# J7AEP_GPU_BXS464_WRAP0_GPU_SS_0_CORE_MMRS register map
Vendor: Texas Instruments
Registers are 64-bit, access per field, reset 0x0 unless marked. A register's access mark holds for its fields unless they carry their own. Offsets are as the file gives them; [hi:lo] are bit positions; lines under a group give offsets from that group; {n}, {i} and the like mark numbered series; 'fields as' and 'values as' point back to an identical list.

## J7AEP_GPU_BXS464_WRAP0_GPU_SS_0_CORE_MMRS (part 4 of 5)
0x2010 CORE_MMRS_RGX_CR_PM_MMU_STACK_POLICY — This register enables the PM to drain pages for MMU from the dedicated mmu free list stack. (no-pagable) It is static register which can not be changed in the run-time.
  [0] OP rw — when this bit is '1', PM will try to drain pages from the dedicated mmu free list stack
0x2018 CORE_MMRS_RGX_CR_PM_TA_MMU_FSTACK_BASE — Effective on loading of the MMU TA free list loading , this register defines the base address of the mmu free list stack being referenced during TA processing.
  [39:4] ADDR rw — 1TB Addressable, 128 bits aligned Base Address for MMU TA free list stack
0x2020 CORE_MMRS_RGX_CR_PM_TA_MMU_FSTACK_STATUS ro — Note: this is the pointer pointing to the MMU TA free stack top. (4KB page pointer)
  [21:0] TOP — This status register indicated the mmu ta context free list pointer status.
0x2028 CORE_MMRS_RGX_CR_PM_TA_MMU_FSTACK — Defines the start of the stack pointer regarding to the MMU free list stack
  [21:0] STARTOF_TOP rw — This register defines the head pointer of the mmu free list in terms of 4K free pages in the free list stack, effective on a loading of the MMU TA free list
0x2030 CORE_MMRS_RGX_CR_PM_START_OF_MMU_TACONTEXT
  [21:0] ALLOCATED_MMUPAGE rw — Start of MMU Freelists TA pages[4KB] on loading of the MMU TA context
0x2038 CORE_MMRS_RGX_CR_PM_TASK_TA_MMU_FSTACK_FREE_LOAD
  [0] PENDING wo — A write into this register will cause the TA MMU free list context to be loaded from the relevant configuration registers
0x2040 CORE_MMRS_RGX_CR_PM_3D_MMU_FSTACK_BASE — Effective on loading of the MMU 3D free list loading , this register defines the base address of the mmu free list stack being referenced during 3D processing.
  fields as CORE_MMRS_RGX_CR_PM_TA_MMU_FSTACK_BASE
0x2048 CORE_MMRS_RGX_CR_PM_3D_MMU_FSTACK_STATUS ro — Note: this is the pointer pointing to the MMU TA free stack top. (4KB page pointer)
  fields as CORE_MMRS_RGX_CR_PM_TA_MMU_FSTACK_STATUS
0x2050 CORE_MMRS_RGX_CR_PM_3D_MMU_FSTACK — Defines the start of the stack pointer regarding to the MMU free list stack Effective on a 3D MMU fstack load
  fields as CORE_MMRS_RGX_CR_PM_TA_MMU_FSTACK
0x2058 CORE_MMRS_RGX_CR_PM_START_OF_MMU_3DCONTEXT — Effective on a 3D MMU fstack load
  [21:0] ALLOCATED_MMUPAGE rw — Start of MMU Freelists 3D pages[4KB] on loading of the MMU TA context
0x2060 CORE_MMRS_RGX_CR_PM_TASK_3D_MMU_FSTACK_FREE_LOAD
  [0] PENDING wo — A write into this register will cause the 3D MMU free list context to be loaded from the relevant configuration registers
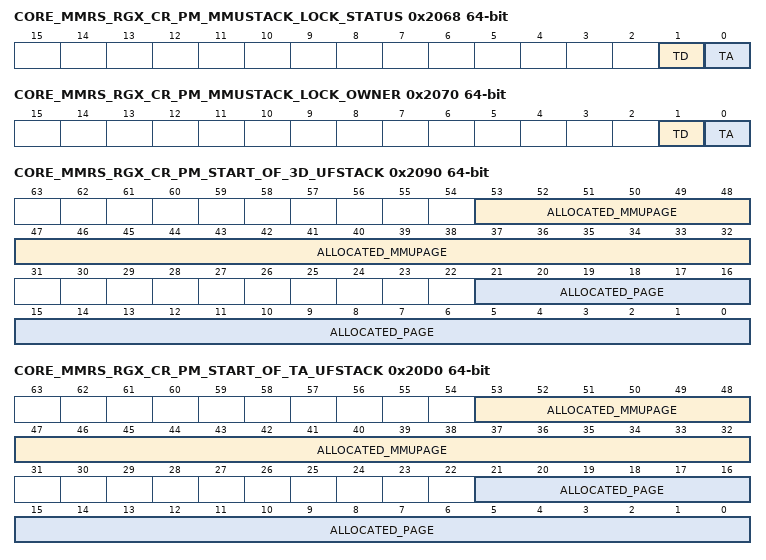
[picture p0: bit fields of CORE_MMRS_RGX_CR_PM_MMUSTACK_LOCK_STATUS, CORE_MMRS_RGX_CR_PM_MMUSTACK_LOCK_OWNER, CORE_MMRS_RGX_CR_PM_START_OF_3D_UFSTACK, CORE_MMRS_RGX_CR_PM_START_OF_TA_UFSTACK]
0x2068 CORE_MMRS_RGX_CR_PM_MMUSTACK_LOCK_STATUS ro
  [1] TD — Bit 1: 3D MMU free list Lock Status. 0 idle/ 1 used
  [0] TA — Bit 0: TA MMU free list Lock Status. 0 idle/ 1 used.
0x2070 CORE_MMRS_RGX_CR_PM_MMUSTACK_LOCK_OWNER ro
  [1] TD — Bit 1 :3D free list Lock owner. 0 PMA / 1 PMD
  [0] TA — Bit 0: TA free list Lock Owner. 0 PMA / 1 PMD.
0x2078 CORE_MMRS_RGX_CR_PM_3D_UFSTACK_BASE — Effective on load of the Unified Free List Stack, this register defines the base address of the unified free list stack being referenced.
  [39:4] ADDR rw — 1TB Addressable, 128 bits aligned Base Address for unified free list stack base address
0x2080 CORE_MMRS_RGX_CR_PM_3D_UFSTACK — Note: each 16GB 4KB addressable page (22 bits) is rounded to dword aligned Effective on load of the Unified Free List Stack,
  [21:0] STARTOF_TOP rw — This register defines the unified free list stack pointer @ loading time. It is 4K page.
0x2088 CORE_MMRS_RGX_CR_PM_3D_UFSTACK_STATUS ro — Note: this is the pointer pointing to the ufstack top. (4KB page pointer)
  [21:0] TOP — This status register indicated the unified free list stack pointer status.
0x2090 CORE_MMRS_RGX_CR_PM_START_OF_3D_UFSTACK — Effective on load of the Unified Free List Stack,
  [53:32] ALLOCATED_MMUPAGE rw — Start of MMU Pages allocated from the Unifed Free List Stack On Loading
  [21:0] ALLOCATED_PAGE rw — Start of TA pages[4KB] on loading of the Unified Free List Stack
0x2098 CORE_MMRS_RGX_CR_PM_3D_UFSTACK_PAGE_STATUS ro
  [21:0] OP — The number of Unified Free list pages currently allocated for the TA
0x20A0 CORE_MMRS_RGX_CR_PM_3D_UFSTACK_MMUPAGE_STATUS ro
  [21:0] OP — The number of Unified Free list pages currently allocated for the MMU
0x20A8 CORE_MMRS_RGX_CR_PM_TASK_3D_UFSTACK_LOAD ro
  [0] PENDING — pending status register corresponding to the ustack loading operation, it will become '1' when this pm_task_ufstack_load being written and deassert until the operation is done
0x20B0 CORE_MMRS_RGX_CR_PM_TASK_TA_UFSTACK_LOAD ro
  fields as CORE_MMRS_RGX_CR_PM_TASK_3D_UFSTACK_LOAD
0x20B8 CORE_MMRS_RGX_CR_PM_TA_UFSTACK_BASE — Effective on load of the Unified Free List Stack, this register defines the base address of the unified free list stack being referenced.
  fields as CORE_MMRS_RGX_CR_PM_3D_UFSTACK_BASE
0x20C0 CORE_MMRS_RGX_CR_PM_TA_UFSTACK — Note: each 16GB 4KB addressable page (22 bits) is rounded to dword aligned Effective on the loading of the Unified Free List Stack,
  fields as CORE_MMRS_RGX_CR_PM_3D_UFSTACK
0x20C8 CORE_MMRS_RGX_CR_PM_TA_UFSTACK_STATUS ro — Note: this is the pointer pointing to the ufstack top. (4KB page pointer)
  fields as CORE_MMRS_RGX_CR_PM_3D_UFSTACK_STATUS
0x20D0 CORE_MMRS_RGX_CR_PM_START_OF_TA_UFSTACK
  fields as CORE_MMRS_RGX_CR_PM_START_OF_3D_UFSTACK
0x20D8 CORE_MMRS_RGX_CR_PM_TA_UFSTACK_PAGE_STATUS ro
  fields as CORE_MMRS_RGX_CR_PM_3D_UFSTACK_PAGE_STATUS
0x20E0 CORE_MMRS_RGX_CR_PM_TA_UFSTACK_MMUPAGE_STATUS ro
  fields as CORE_MMRS_RGX_CR_PM_3D_UFSTACK_MMUPAGE_STATUS
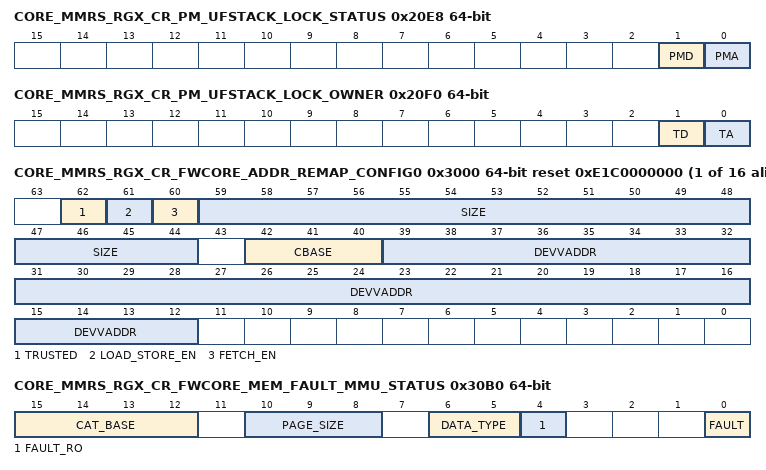
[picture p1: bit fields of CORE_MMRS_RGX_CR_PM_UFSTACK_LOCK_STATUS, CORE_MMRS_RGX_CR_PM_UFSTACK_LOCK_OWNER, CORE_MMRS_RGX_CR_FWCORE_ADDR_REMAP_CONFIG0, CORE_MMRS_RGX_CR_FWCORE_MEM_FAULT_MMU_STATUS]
0x20E8 CORE_MMRS_RGX_CR_PM_UFSTACK_LOCK_STATUS ro — In rogue architecture, there is a unified free list whereby shared across multiple context. This lock status indicating the stack owner at the time being. Note PMA and PMD can not acquire the lock @ the same time
  [1] PMD — Bit 1: Page DeAllocation Manger is grabing the lock. 0:idle/ 1 used.
  [0] PMA — Bit 0: Page Allocation Manger is grabing the lock. 0:idle/ 1 used.
0x20F0 CORE_MMRS_RGX_CR_PM_UFSTACK_LOCK_OWNER ro
  fields as CORE_MMRS_RGX_CR_PM_MMUSTACK_LOCK_OWNER
0x20F8 CORE_MMRS_RGX_CR_PM_UFSTACK_POLICY — This register enables the PM to drain pages from the unified free list stack It is a static configuration register
  [0] OP rw — when this bit is '1', PM will try to drain pages from the unified free list stack as long as the ta free list do not have enough pages for the allocation
0x2100 CORE_MMRS_RGX_CR_PM_VFP_TRAN_EN — This register enables the PM to another level of transfrom which is from Virtial Page to VirtualPhysical Page number
  [0] OP rw — when this bit is '1', PM will try to another level of lookup between virtual page and the virtual physical page
0x2108 CORE_MMRS_RGX_CR_PM_TA_VFP_TABLE_BASE — Effective on loading TA context, this register defines the base address of the virtual-physical page table during TA processing.
  [39:4] ADDR rw — 1TB Addressable, 128 bits aligned Base Address for TA context page tables in the DPM module
0x2110 CORE_MMRS_RGX_CR_PM_3D_VFP_TABLE_BASE — Effective on loading 3D context, this register defines the base address of the virtual-physical page table during 3D processing.
  [39:4] ADDR rw — 1TB Addressable, 128 bits aligned Base Address for 3D context page tables in the DPM module
{0x3000+8i} CORE_MMRS_RGX_CR_FWCORE_ADDR_REMAP_CONFIG{i} reset 0xE1C0000000 (i=0..15) — Override swerv memory access for this region
  [62] TRUSTED rw — Set whether accesses in the this region are trusted
  [61] LOAD_STORE_EN rw — Region enabled for loads/stores
  [60] FETCH_EN rw — Region enabled for instruction fetches
  [59:44] SIZE rw — Region mapped window size
  [42:40] CBASE rw — MMU catalogue base index. Indices 0-7 are supported
  [39:12] DEVVADDR rw — Base output address [4k aligned]
0x3090 CORE_MMRS_RGX_CR_FWCORE_BOOT — Boot the RISCV CPU
  [0] ENABLE rw
0x3098 CORE_MMRS_RGX_CR_FWCORE_RESET_ADDR reset 0xC0000000 — Swerv reset address
  [31:1] ADDR rw — Reset address for the core
0x30A0 CORE_MMRS_RGX_CR_FWCORE_WRAPPER_NMI_ADDR reset 0xC0001000 — Non-Maskable Interrupt address
  [31:1] ADDR rw
0x30A8 CORE_MMRS_RGX_CR_FWCORE_WRAPPER_NMI_EVENT — Issue a Non-Maskable Interrupt to RISCV
  [0] TRIGGER_EN rw
0x30B0 CORE_MMRS_RGX_CR_FWCORE_MEM_FAULT_MMU_STATUS — Indicates a fault has occurred on the CPU MMU and provides details of the fault. Writing any value will clear the fault and allow subsequent faults to be reported.
  [15:12] CAT_BASE rw — Catalogue base address number
  [10:8] PAGE_SIZE rw
  [6:5] DATA_TYPE rw — MMU data type that was invalid [on valid fault]
  [4] FAULT_RO rw — Indicates read-only fault['1'] or valid fault['0']
  [0] FAULT rw — Indicates a fault has occured
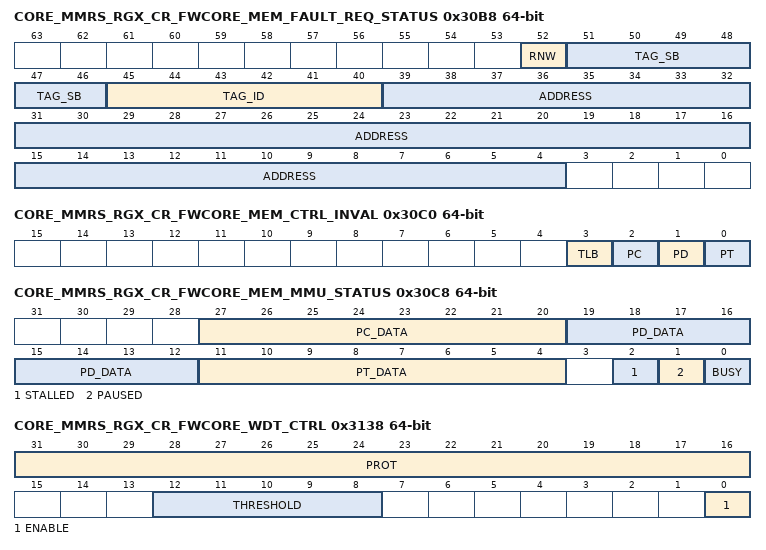
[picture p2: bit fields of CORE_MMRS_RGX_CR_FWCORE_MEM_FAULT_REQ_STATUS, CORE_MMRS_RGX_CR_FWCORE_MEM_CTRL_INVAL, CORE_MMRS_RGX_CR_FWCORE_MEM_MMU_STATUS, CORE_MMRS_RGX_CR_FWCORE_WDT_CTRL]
0x30B8 CORE_MMRS_RGX_CR_FWCORE_MEM_FAULT_REQ_STATUS ro — Provides details of the request that faulted on the CPU MMU
  [52] RNW, [51:46] TAG_SB, [45:40] TAG_ID, [39:4] ADDRESS
0x30C0 CORE_MMRS_RGX_CR_FWCORE_MEM_CTRL_INVAL — Invalidation bits allowing CPU BIF/MMU to clear when invalidation complete
  [3] TLB rw, [2] PC rw, [1] PD rw, [0] PT rw
0x30C8 CORE_MMRS_RGX_CR_FWCORE_MEM_MMU_STATUS ro — General CPU MMU status
  [27:20] PC_DATA, [19:12] PD_DATA, [11:4] PT_DATA, [2] STALLED, [1] PAUSED, [0] BUSY
0x30D8 CORE_MMRS_RGX_CR_FWCORE_MEM_READS_EXT_STATUS ro — Outstanding read data external to CPU MMU
  [11:0] MMU
0x30E0 CORE_MMRS_RGX_CR_FWCORE_MEM_READS_INT_STATUS ro — Outstanding 256-bit read data in return data FIFO for CPU MMU
  [10:0] MMU
0x30E8 CORE_MMRS_RGX_CR_FWCORE_WRAPPER_FENCE — Writing to this register offset will cause the CPU wrapper to emit a write fence to memory. Reading from this register has no effect. This register does not actually exist anywhere in RTL - it is a reserved address.
  [0] ID rw
{0x30F0+8i} CORE_MMRS_RGX_CR_FWCORE_MEM_CAT_BASE{i} (i=0..7)
  [39:12] ADDR rw
0x3130 CORE_MMRS_RGX_CR_FWCORE_WDT_RESET — A '1' may be written to this register to reset the watchdog timer count. The count will be reset to 0x0 whether or not the timer is currently enabled.
  [0] EN wo
0x3138 CORE_MMRS_RGX_CR_FWCORE_WDT_CTRL — Watchdog timer control register.
  [31:16] PROT wo — Writes to this register must set these bits to 0xABCD for the writes to THRESHOLD and ENABLE to take effect. These bits are read as 0x0000
  [12:8] THRESHOLD wo — Logarithmic threshold. When the counter bit indexed by the value in this field transitions from 0 to 1 the WDT module output pulse is asserted and the count is reset to 0.
  [0] ENABLE wo — '1' - WDT enabled. '0' - WDT disabled.
0x3140 CORE_MMRS_RGX_CR_FWCORE_WDT_COUNT ro — Read only register returns the current value of the watchdog timer count.
  [31:0] VALUE
0x3148 CORE_MMRS_RGX_CR_RISCV_MTIME_SET rw — Writing to this register updates the Timer counter. On the following ticks the counter will be incremented based on the newly written value.
  [63:0] VALUE
0x3150 CORE_MMRS_RGX_CR_RISCV_MTIME_CMP rw — Writing to this register updates the Timer compare value and at the same time clears the sticky bit of the timer interrupt output.
  [63:0] VALUE
0x3158 CORE_MMRS_RGX_CR_RISCV_MTIME_STAT ro — Shows the momentary value of the 64 bit Timer counter.
  [63:0] VALUE
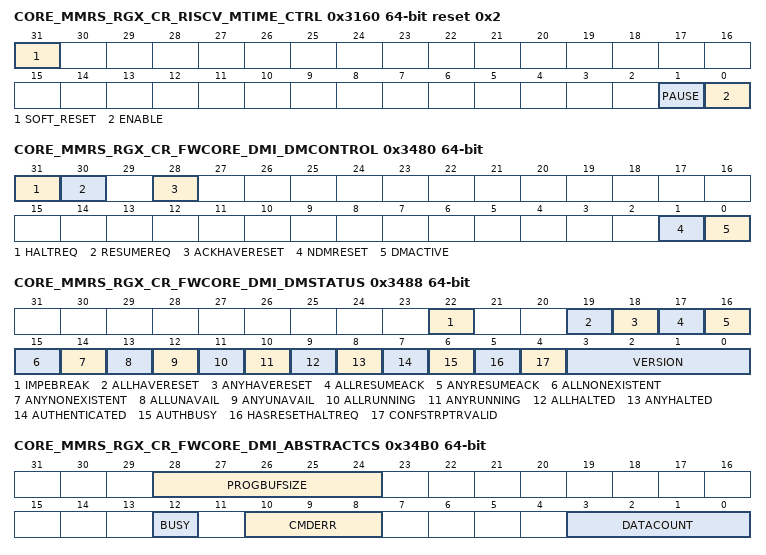
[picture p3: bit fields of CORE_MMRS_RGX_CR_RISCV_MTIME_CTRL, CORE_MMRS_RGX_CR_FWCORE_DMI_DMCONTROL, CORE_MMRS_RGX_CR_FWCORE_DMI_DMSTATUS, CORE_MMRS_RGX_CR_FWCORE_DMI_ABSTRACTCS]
0x3160 CORE_MMRS_RGX_CR_RISCV_MTIME_CTRL reset 0x2 — Control register.
  [31] SOFT_RESET rw — When high, the counter, the MTIME_SET & MTIME_CMP registers and the sticky interrupt are all forced to zero
  [1] PAUSE rw — When high, the timer is not being incremented by tick pulses, but can still be written using the MTIME_SET registers.
  [0] ENABLE rw — When high, the timer interrupt output is enabled. The counter itself is not affected by this bit.
0x3168 CORE_MMRS_RGX_CR_FWCORE_IDLE reset 0x1 — Top-level idle control register
  [0] ENABLE rw — Set to 0x0 overwrites the value of GPU_IDLE to 0x0, set to 0x1 makes GPU Idle dependent on top level idles
{0x3400+8i} CORE_MMRS_RGX_CR_FWCORE_DMI_RESERVED{i:02} ro (i=0..3) — This address is mapped to the FW CPU debug port. Do not use
0x3420 CORE_MMRS_RGX_CR_FWCORE_DMI_DATA0 — RISC-V Debug Module Interface - Basic read/write register that may be read or changed by abstract commands.
  [31:0] VAL rw
0x3428 CORE_MMRS_RGX_CR_FWCORE_DMI_DATA1 — RISC-V Debug Module Interface - Basic read/write register that may be read or changed by abstract commands.
  [31:0] VAL rw
{0x33E0+8i} CORE_MMRS_RGX_CR_FWCORE_DMI_RESERVED{i} ro (i=10..19) — This address is mapped to the FW CPU debug port. Do not use
0x3480 CORE_MMRS_RGX_CR_FWCORE_DMI_DMCONTROL — RISC-V Debug Module Interface - This register controls the overall Debug Module as well as the currently selected harts.
  [31] HALTREQ rw, [30] RESUMEREQ rw, [28] ACKHAVERESET rw, [1] NDMRESET rw, [0] DMACTIVE rw
0x3488 CORE_MMRS_RGX_CR_FWCORE_DMI_DMSTATUS ro — RISC-V Debug Module Interface - This register reports status for the overall Debug Module as well as the currently selected harts.
  [22] IMPEBREAK, [19] ALLHAVERESET, [18] ANYHAVERESET, [17] ALLRESUMEACK, [16] ANYRESUMEACK, [15] ALLNONEXISTENT, [14] ANYNONEXISTENT, [13] ALLUNAVAIL, [12] ANYUNAVAIL, [11] ALLRUNNING, [10] ANYRUNNING, [9] ALLHALTED, [8] ANYHALTED, [7] AUTHENTICATED, [6] AUTHBUSY, [5] HASRESETHALTREQ, [4] CONFSTRPTRVALID, [3:0] VERSION
{0x33F0+8i} CORE_MMRS_RGX_CR_FWCORE_DMI_RESERVED{i} ro (i=20..23) — This address is mapped to the FW CPU debug port. Do not use
0x34B0 CORE_MMRS_RGX_CR_FWCORE_DMI_ABSTRACTCS — RISC-V Debug Module Interface - Abstract Control and Status
  [28:24] PROGBUFSIZE rw, [12] BUSY rw, [10:8] CMDERR rw, [3:0] DATACOUNT rw
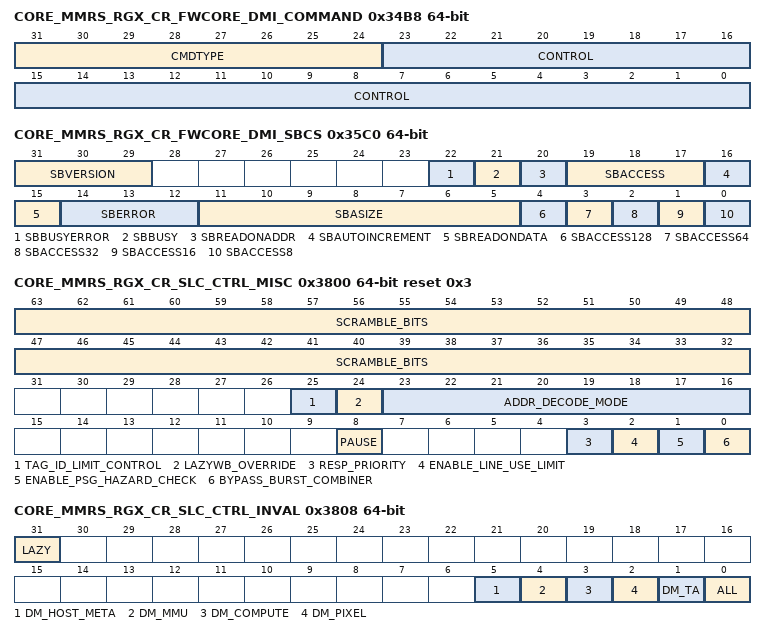
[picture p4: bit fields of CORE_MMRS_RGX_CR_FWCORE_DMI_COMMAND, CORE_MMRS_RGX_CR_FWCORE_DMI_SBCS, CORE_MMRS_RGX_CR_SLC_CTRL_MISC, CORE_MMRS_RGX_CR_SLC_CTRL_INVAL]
0x34B8 CORE_MMRS_RGX_CR_FWCORE_DMI_COMMAND — RISC-V Debug Module Interface - Abstract Command
  [31:24] CMDTYPE rw, [23:0] CONTROL rw
{0x33D0+8i} CORE_MMRS_RGX_CR_FWCORE_DMI_RESERVED{i} ro (i=30..39) — This address is mapped to the FW CPU debug port. Do not use
{0x2B60+8i} CORE_MMRS_RGX_CR_FWCORE_DMI_RESERVED{i} ro (i=310..331) — This address is mapped to the FW CPU debug port. Do not use
0x35C0 CORE_MMRS_RGX_CR_FWCORE_DMI_SBCS — RISC-V Debug Module Interface - System Bus Access Control and Status
  [31:29] SBVERSION rw, [22] SBBUSYERROR rw, [21] SBBUSY rw, [20] SBREADONADDR rw, [19:17] SBACCESS rw, [16] SBAUTOINCREMENT rw, [15] SBREADONDATA rw, [14:12] SBERROR rw, [11:5] SBASIZE rw, [4] SBACCESS128 rw, [3] SBACCESS64 rw, [2] SBACCESS32 rw, [1] SBACCESS16 rw, [0] SBACCESS8 rw
0x35C8 CORE_MMRS_RGX_CR_FWCORE_DMI_SBADDRESS0 — RISC-V Debug Module Interface - System Bus Address
  [31:0] ADDRESS rw
0x35D0 CORE_MMRS_RGX_CR_FWCORE_DMI_RESERVED40 ro — This address is mapped to the FW CPU debug port. Do not use
0x35D8 CORE_MMRS_RGX_CR_FWCORE_DMI_RESERVED41 ro — This address is mapped to the FW CPU debug port. Do not use
{0x35E0+8i} CORE_MMRS_RGX_CR_FWCORE_DMI_SBDATA{i} (i=0..3) — RISC-V Debug Module Interface - System Bus Data Words
  [31:0] DATA rw
0x3600 CORE_MMRS_RGX_CR_FWCORE_DMI_HALTSUM0 ro — RISC-V Debug Module Interface - Halt Summary 0
  [31:0] VAL
0x3800 CORE_MMRS_RGX_CR_SLC_CTRL_MISC reset 0x3 — SLC control registers
  [63:32] SCRAMBLE_BITS rw — Pattern of bits used to determine the Cache Bank in Address Decode mode 0x21. The actual Cache Bank to use is determined by indexing into the 32 Scramble Bits using the 5 LSB's of the Hash result and then XORing this with Bit 6 of the incoming address to give a single bit result
  [25] TAG_ID_LIMIT_CONTROL rw — Controls the number of external memory tag IDs available to SLC
  [24] LAZYWB_OVERRIDE rw — Override cache policy of requests with lazy write back to write back
  [23:16] ADDR_DECODE_MODE rw — Address decoding used to determine cache bank from the address: 0x00 = Bit 6 = 64 byte 0x01 = Bit 7 = 128 byte 0x10 = Simple XOR based address hash 1, see SLC TRM 0x11 = Simple XOR based address hash 2, see SLC TRM 0x20 = PVR address hash using an XOR reduce of the hash, see SLC TRM 0x21 = PVR address hash using Scramble Bits above, see SLC TRM
  [8] PAUSE rw — Pause the SLC
  [3] RESP_PRIORITY rw — Priority setting between Hit and Miss on return response. Default is round robin and set to 1 if miss needs priority over hit
  [2] ENABLE_LINE_USE_LIMIT rw — Enable the use of cache line limits
  [1] ENABLE_PSG_HAZARD_CHECK rw — Enable the hazard checking of PSG writes, only turn off if strict write ordering is guaranteed in the memory fabric
  [0] BYPASS_BURST_COMBINER rw — Disable the burst combiner on the external memory interface
0x3808 CORE_MMRS_RGX_CR_SLC_CTRL_INVAL — SLC Invalidate control. Note that per Data Master operations only invalidate entries that have been referenced solely by the specified Data Master, any cache lines referenced by multiple Data Masters will not be affected by a per Data Master invalidate operation and will remain valid.
  [31] LAZY wo — Advanced mode of operation whereby other requestors are not blocked whilst the Invalidate is in progress
  [5] DM_HOST_META wo — When set, invalidate all SLC entries referenced solely by the HOST or META
  [4] DM_MMU wo — When set, invalidate all SLC entries referenced solely by the MMU
  [3] DM_COMPUTE wo — When set, invalidate all SLC entries referenced solely by the COMPUTE data master
  [2] DM_PIXEL wo — When set, invalidate all SLC entries referenced solely by the PIXEL data master
  [1] DM_TA wo — When set, invalidate all SLC entries referenced solely by the TA group which includes VERTEX, TESSELLATOR & STREAM_OUT data masters
  [0] ALL wo — When set, invalidate all SLC entries
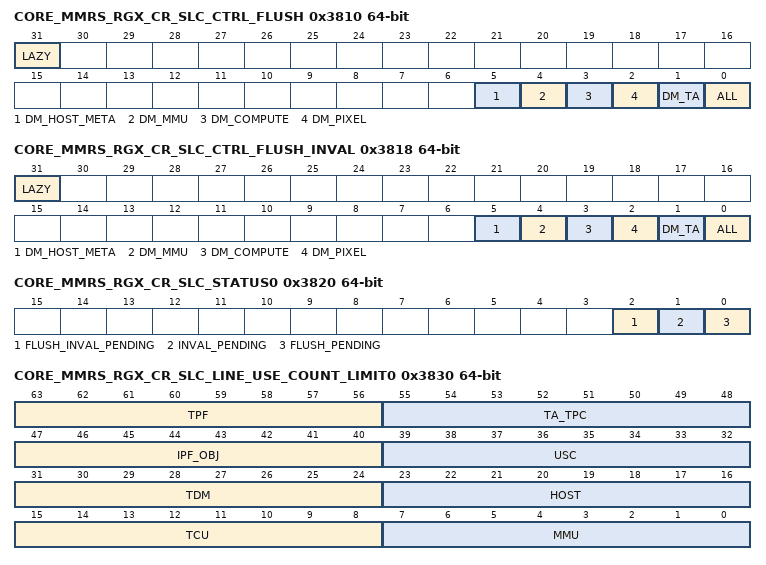
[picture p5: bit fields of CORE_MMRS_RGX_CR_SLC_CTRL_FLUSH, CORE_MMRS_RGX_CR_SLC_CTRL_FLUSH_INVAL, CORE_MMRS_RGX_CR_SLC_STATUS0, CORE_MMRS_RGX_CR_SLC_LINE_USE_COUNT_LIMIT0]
0x3810 CORE_MMRS_RGX_CR_SLC_CTRL_FLUSH — SLC Flush control. Note that per Data Master operations will flush any cache lines that have been made dirty by any writes from the specified Data Master.
  [31] LAZY wo — Advanced mode of operation whereby other requestors are not blocked whilst the Flush is in progress
  [5] DM_HOST_META wo — When set, flush all SLC entries made dirty by the HOST or META
  [4] DM_MMU wo — When set, flush all SLC entries made dirty by the MMU
  [3] DM_COMPUTE wo — When set, flush all SLC entries made dirty by the COMPUTE data master
  [2] DM_PIXEL wo — When set, flush all SLC entries made dirty by the PIXEL data master
  [1] DM_TA wo — When set, flush all SLC entries made dirty by the TA group which includes VERTEX, TESSELLATOR & STREAM_OUT data masters
  [0] ALL wo — When set, flush all SLC entries
0x3818 CORE_MMRS_RGX_CR_SLC_CTRL_FLUSH_INVAL — SLC Flush & Invalidate control. Note that per Data Master operations will flush any cache lines that have been made dirty by any writes from the specified Data Master. Combined Invalidate operation then only invalidates entries that have been referenced solely by the specified Data Master, any cache lines referenced by multiple Data Masters will not be affected by a per Data Master invalidate operation and will remain valid.
  [31] LAZY wo — Advanced mode of operation whereby other requestors are not blocked whilst the Flush Invalidate is in progress
  [5] DM_HOST_META wo — When set, flush all SLC entries made dirty by the HOST or META, then invalidate all SLC entries referenced solely by the HOST or META
  [4] DM_MMU wo — When set, flush all SLC entries made dirty by the MMU, then invalidate all SLC entries referenced solely by the MMU
  [3] DM_COMPUTE wo — When set, flush all SLC entries made dirty by the COMPUTE data master, then invalidate all SLC entries referenced solely by the COMPUTE data master
  [2] DM_PIXEL wo — When set, flush all SLC entries made dirty by the PIXEL data master, then invalidate all SLC entries referenced solely by the PIXEL data master
  [1] DM_TA wo — When set, flush all SLC entries made dirty by the TA group which includes VERTEX, TESSELLATOR & STREAM_OUT data masters, then invalidate all SLC entries referenced solely by the TA group which includes VERTEX, TESSELLATOR & STREAM_OUT data masters
  [0] ALL wo — When set, flush all SLC entries, then invalidate all SLC entries
0x3820 CORE_MMRS_RGX_CR_SLC_STATUS0 ro — Current status of Flush / Invalidate operations within the SLC
  [2] FLUSH_INVAL_PENDING — 1 indicates there is a pending request to perform a combined Flush Invalidate on the SLC
  [1] INVAL_PENDING — 1 indicates there is a pending request to Invalidate the SLC
  [0] FLUSH_PENDING — 1 indicates there is a pending request to Flush the SLC
0x3828 CORE_MMRS_RGX_CR_SLC_CTRL_BYPASS reset 0x3D1F00000000 — SLC Bypass control
  [59] REQ_TFBC_COMP_ZLS rw — Bypass SLC for TFBC_COMP ZLS requestor
  [58] REQ_TFBC_DECOMP_ZLS_HEADER rw — Bypass SLC for TFBC_DECOMP ZLS Header requestor
  [57] REQ_TFBC_DECOMP_TCU_HEADER rw — Bypass SLC for TFBC_DECOMP TCU Header requestor
  [56] REQ_TFBC_DECOMP_ZLS_DATA rw — Bypass SLC for TFBC_DECOMP ZLS Delta requestor
  [55] REQ_TFBC_DECOMP_TCU_DATA rw — Bypass SLC for TFBC_DECOMP TCU Delta requestor
  [54] REQ_TFBC_COMP_PBE rw — Bypass SLC for TFBC_COMP PBE requestor
  [53] REQ_TCU_DM_COMPUTE rw — Bypass SLC when DM is COMPUTE for TCU requests
  [52] PDSRW_NOLINEFILL rw — PDSRW nolinefill set
  [51] PBE_NOLINEFILL rw — PBE nolinefill set
  [49] REQ_IPF_RREQ rw — Bypass SLC for IPF [RREQ] requestor
  [48] REQ_IPF_CREQ rw — Bypass SLC for IPF [CREQ] requestor
  [47] REQ_IPF_PREQ rw — Bypass SLC for IPF [PREQ] requestor
  [46] REQ_IPF_DBSC rw — Bypass SLC for IPF [DBSC] requestor
  [45] REQ_TCU rw — Bypass SLC for TCU requests
  [44] REQ_PBE rw — Bypass SLC for PBE requestor
  [43] REQ_ISP rw — Bypass SLC for the ISP requestor
  [42] REQ_PM rw — Bypass SLC for the PM requestor
  [40] REQ_CDM rw — Bypass SLC for the CDM requestor
  [39] REQ_TSPF_PDS_STATE rw — Bypass SLC for the TSPF PDS STATE requestor
  [38] REQ_TSPF_DB rw — Bypass SLC for the TSPF DB requestor
  [37] REQ_TSPF_VTX_VAR rw — Bypass SLC for the TSPF VTX VAR requestor
  [36] REQ_VDM rw — Bypass SLC for VDM requestor
  [35] REQ_TA_PSG_STREAM rw — Bypass SLC for the TA [PSG Stream] requestor
  [34] REQ_TA_PSG_REGION rw — Bypass SLC for the TA [PSG Region] requestor
  [33] REQ_TA_VCE rw — Bypass SLC for the TA [VCE] requestor
  [32] REQ_TA_PPP rw — Bypass SLC for the TA [PPP] requestor
  [30] DM_PM_ALIST rw — Bypass SLC for the PM_ALIST data master
  [29] DM_PB_TE rw — Bypass SLC for the PB_TE data master
  [28] DM_PB_VCE rw — Bypass SLC for the PB_VCE data master
  [25] REQ_IPF_CPF rw — Bypass SLC for IPF [CPF] requestor
  [24] REQ_TPU rw — Bypass SLC for TPU requests coming from the MCU requestor
  [21] BYP_CC_N rw — Bypass SLC when Cache Coherency bit is not set
  [20] BYP_CC rw — Bypass SLC when Cache Coherency bit is set
  [19] REQ_MCU rw — Bypass SLC for the MCU requestor
  [18] REQ_PDS rw — Bypass SLC for the PDS requestor
  [17] REQ_TPF rw — Bypass SLC for the TPF requestor
  [16] REQ_TA_TPC rw — Bypass SLC for the TA [Tail Pointer Cache data] requestor
  [14] REQ_USC rw — Bypass SLC for the USC requestor
  [13] REQ_META rw — Bypass SLC for the META requestor
  [12] REQ_HOST rw — Bypass SLC for the Host requestor
  [11] REQ_MMU_PT rw — Bypass SLC for the MMU requestor [Page Table data]
  [10] REQ_MMU_PD rw — Bypass SLC for the MMU requestor [Page Directory data]
  [9] REQ_MMU_PC rw — Bypass SLC for the MMU requestor [Page Catalogue data]
  [5] DM_HOST_META rw — Bypass SLC the HOST/META data master
  [4] DM_MMU rw — Bypass SLC the MMU data master
  [3] DM_COMPUTE rw — Bypass SLC the COMPUTE data master
  [2] DM_PIXEL rw — Bypass SLC for the PIXEL data master
  [1] DM_TA rw — Bypass SLC for the TA group which includes VERTEX, TESSELLATOR & STREAM_OUT data masters
  [0] ALL rw — Bypass SLC for all requesters
0x3830 CORE_MMRS_RGX_CR_SLC_LINE_USE_COUNT_LIMIT0 rw — Define the maximum number of cache lines allowed to be allocated to each requester within the SLC. Note that values are specified per bank as a multiple of 4 cache lines with values of 0x0 denoting no limit. Also note that the specified values operate as soft limits rather than hard limits and at any given time a requestor may temporarily exceed its given cacheline limit by a small amount.
  [63:56] TPF — Maximum number of cachelines allocated to the TPF requestor
  [55:48] TA_TPC — Maximum number of cachelines allocated to the TA [Tail Pointer Cache data] requestor
  [47:40] IPF_OBJ — Maximum number of cachelines allocated to the IPF [Object data] requestor
  [39:32] USC — Maximum number of cachelines allocated to the USC requestor
  [31:24] TDM — Maximum number of cachelines allocated to the TDM requestor
  [23:16] HOST — Maximum number of cachelines allocated to the HOST requestor
  [15:8] TCU — Maximum number of cachelines allocated to the TCU requestor
  [7:0] MMU — Maximum number of cachelines allocated to the MMU requestor
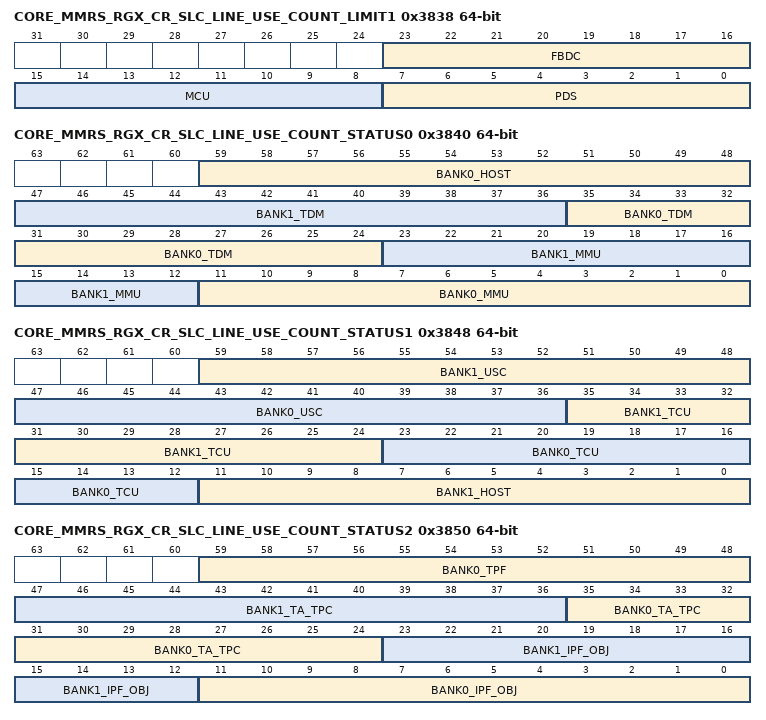
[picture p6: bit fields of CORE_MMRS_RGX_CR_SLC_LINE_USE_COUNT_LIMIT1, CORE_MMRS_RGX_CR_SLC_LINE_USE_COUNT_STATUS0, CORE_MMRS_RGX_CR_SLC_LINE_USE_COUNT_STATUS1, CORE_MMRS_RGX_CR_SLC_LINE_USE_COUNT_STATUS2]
0x3838 CORE_MMRS_RGX_CR_SLC_LINE_USE_COUNT_LIMIT1 — Define the maximum number of cache lines allowed to be allocated to each requester within the SLC. Note that values are specified per bank as a multiple of 4 cache lines with values of 0x0 denoting no limit. Also note that the specified values operate as soft limits rather than hard limits and at any given time a requestor may temporarily exceed its given cacheline limit by a small amount.
  [23:16] FBDC rw — Maximum number of cachelines allocated to the FBDC requestor
  [15:8] MCU rw — Maximum number of cachelines allocated to the MCU requestor
  [7:0] PDS rw — Maximum number of cachelines allocated to the PDS requestor
0x3840 CORE_MMRS_RGX_CR_SLC_LINE_USE_COUNT_STATUS0 ro — Number of cache lines currently allocated to each requester within the SLC. Values will constantly change when the core is active but will give a representative snapshot of cache usage.
  [59:48] BANK0_HOST — Number of cache lines in bank 0 currently allocated to the HOST
  [47:36] BANK1_TDM — Number of cache lines in bank 1 currently allocated to the TDM
  [35:24] BANK0_TDM — Number of cache lines in bank 0 currently allocated to the TDM
  [23:12] BANK1_MMU — Number of cache lines in bank 1 currently allocated to the MMU
  [11:0] BANK0_MMU — Number of cache lines in bank 0 currently allocated to the MMU
0x3848 CORE_MMRS_RGX_CR_SLC_LINE_USE_COUNT_STATUS1 ro — Number of cache lines currently allocated to each requester within the SLC. Values will constantly change when the core is active but will give a representative snapshot of cache usage.
  [59:48] BANK1_USC — Number of cache lines in bank 1 currently allocated to the USC
  [47:36] BANK0_USC — Number of cache lines in bank 0 currently allocated to the USC
  [35:24] BANK1_TCU — Number of cache lines in bank 1 currently allocated to the TCU
  [23:12] BANK0_TCU — Number of cache lines in bank 0 currently allocated to the TCU
  [11:0] BANK1_HOST — Number of cache lines in bank 1 currently allocated to the HOST
0x3850 CORE_MMRS_RGX_CR_SLC_LINE_USE_COUNT_STATUS2 ro — Number of cache lines currently allocated to each requester within the SLC. Values will constantly change when the core is active but will give a representative snapshot of cache usage.
  [59:48] BANK0_TPF — Number of cache lines in bank 0 currently allocated to the TPF
  [47:36] BANK1_TA_TPC — Number of cache lines in bank 1 currently allocated to the TA [Tail Pointer Cache data]
  [35:24] BANK0_TA_TPC — Number of cache lines in bank 0 currently allocated to the TA [Tail Pointer Cache data]
  [23:12] BANK1_IPF_OBJ — Number of cache lines in bank 1 currently allocated to the IPF [Object data]
  [11:0] BANK0_IPF_OBJ — Number of cache lines in bank 0 currently allocated to the IPF [Object data]
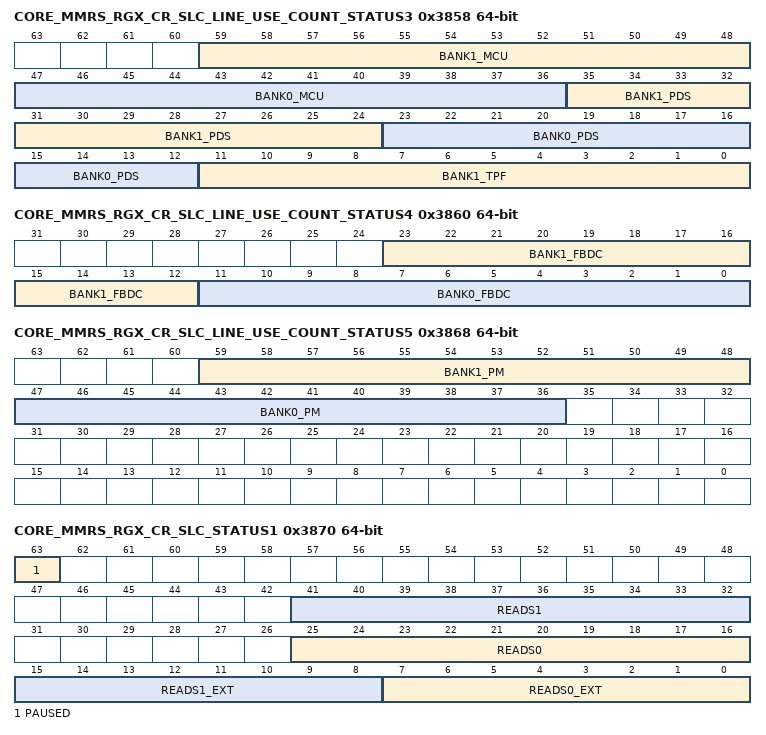
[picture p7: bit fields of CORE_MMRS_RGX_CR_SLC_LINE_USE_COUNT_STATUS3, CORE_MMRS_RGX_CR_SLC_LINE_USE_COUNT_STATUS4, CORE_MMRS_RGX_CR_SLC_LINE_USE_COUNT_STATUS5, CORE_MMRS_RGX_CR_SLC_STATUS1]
0x3858 CORE_MMRS_RGX_CR_SLC_LINE_USE_COUNT_STATUS3 ro — Number of cache lines currently allocated to each requester within the SLC. Values will constantly change when the core is active but will give a representative snapshot of cache usage.
  [59:48] BANK1_MCU — Number of cache lines in bank 1 currently allocated to the MCU
  [47:36] BANK0_MCU — Number of cache lines in bank 0 currently allocated to the MCU
  [35:24] BANK1_PDS — Number of cache lines in bank 1 currently allocated to the PDS
  [23:12] BANK0_PDS — Number of cache lines in bank 0 currently allocated to the PDS
  [11:0] BANK1_TPF — Number of cache lines in bank 1 currently allocated to the TPF
0x3860 CORE_MMRS_RGX_CR_SLC_LINE_USE_COUNT_STATUS4 ro — Number of cache lines currently allocated to each requester within the SLC. Values will constantly change when the core is active but will give a representative snapshot of cache usage.
  [23:12] BANK1_FBDC — Number of cache lines in bank 1 currently allocated to the FBDC
  [11:0] BANK0_FBDC — Number of cache lines in bank 0 currently allocated to the FBDC
0x3868 CORE_MMRS_RGX_CR_SLC_LINE_USE_COUNT_STATUS5 ro — Number of cache lines currently allocated to each requester within the SLC. Values will constantly change when the core is active but will give a representative snapshot of cache usage.
  [59:48] BANK1_PM — Number of cache lines in bank 1 currently allocated to the PM core
  [47:36] BANK0_PM — Number of cache lines in bank 0 currently allocated to the PM core
0x3870 CORE_MMRS_RGX_CR_SLC_STATUS1 ro — Current status of the SLC
  [63] PAUSED — All cache banks are Paused
  [41:32] READS1 — Number of items of read data SLC bank 1 has in internal pipeline FIFO's
  [25:16] READS0 — Number of items of read data SLC bank 0 has in internal pipeline FIFO's
  [15:8] READS1_EXT — Number of items of read data SLC bank 1 has outstanding from external memory
  [7:0] READS0_EXT — Number of items of read data SLC bank 0 has outstanding from external memory
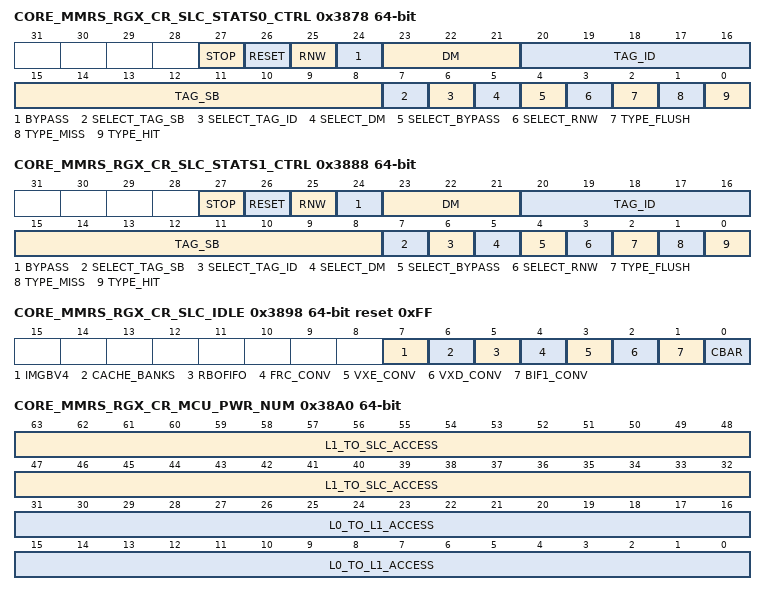
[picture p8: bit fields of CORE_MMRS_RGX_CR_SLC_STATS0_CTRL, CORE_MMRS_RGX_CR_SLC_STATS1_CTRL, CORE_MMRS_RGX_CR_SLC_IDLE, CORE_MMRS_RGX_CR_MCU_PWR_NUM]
0x3878 CORE_MMRS_RGX_CR_SLC_STATS0_CTRL — Configuration of the SLC Stats counters inside SLC bank 0. The type fields should be set to define the events that should be counted, then constraints should be added to specify particular requestors or types of request that should be counted.
  [27] STOP rw — Pause counting whilst this bit is set
  [26] RESET rw — Reset counter
  [25] RNW rw — If constraint set, 0x0 count only writes 0x1 count only reads
  [24] BYPASS rw — If constraint set, 0x0 count cached requests 0x1 count bypassed requests
  [23:21] DM rw — If constraint set, count only requests for the specified Data Master
  [20:16] TAG_ID rw — If constraint set, count only requests with the specified Tag ID
  [15:8] TAG_SB rw — If constraint set, count only requests with the specified sideband Tag
  [7] SELECT_TAG_SB rw — Include Tag sideband in constraints
  [6] SELECT_TAG_ID rw — Include Tag ID in constraints
  [5] SELECT_DM rw — Include Data Master in constraints
  [4] SELECT_BYPASS rw — Include Bypass enable in constraints
  [3] SELECT_RNW rw — Include Wead/Write select in constraints
  [2] TYPE_FLUSH rw — Count number of cache lines flushed
  [1] TYPE_MISS rw — Count number of misses
  [0] TYPE_HIT rw — Count number of hits
0x3880 CORE_MMRS_RGX_CR_SLC_STATS0_OUTPUT ro — Output of the SLC Stats counter inside SLC bank 0.
  [31:0] VALUE — Value of counter 0
0x3888 CORE_MMRS_RGX_CR_SLC_STATS1_CTRL — Configuration of the SLC Stats counters inside SLC bank 1. The type fields should be set to define the events that should be counted, then constraints should be added to specify particular requestors or types of request that should be counted.
  fields as CORE_MMRS_RGX_CR_SLC_STATS0_CTRL
0x3890 CORE_MMRS_RGX_CR_SLC_STATS1_OUTPUT ro — Output of the SLC Stats counter inside SLC bank 1.
  [31:0] VALUE — Value of counter 1
0x3898 CORE_MMRS_RGX_CR_SLC_IDLE ro reset 0xFF
  [7] IMGBV4 — IMG Bus v4 Module IDLE
  [6] CACHE_BANKS — Cache Bank IDLEs
  [5] RBOFIFO — Read Burst Order FIFO Module IDLE
  [4] FRC_CONV — FRC Module IDLE
  [3] VXE_CONV — Video Encode Converter Module IDLE
  [2] VXD_CONV — Video Decode Converter Module IDLE
  [1] BIF1_CONV — BIF128->256 Converter Module IDLE
  [0] CBAR — CrossBar Module IDLE
0x38A0 CORE_MMRS_RGX_CR_MCU_PWR_NUM ro — Power Monitoring register
  [63:32] L1_TO_SLC_ACCESS — Number of L1 to SLC accesses
  [31:0] L0_TO_L1_ACCESS — Number of L0 to L1 accesses. Both L0s in a DUST added together
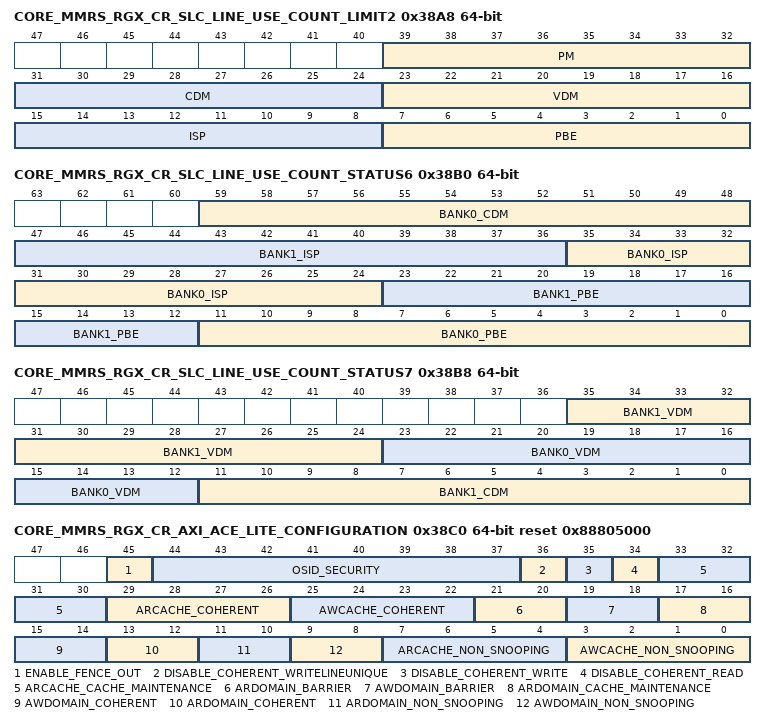
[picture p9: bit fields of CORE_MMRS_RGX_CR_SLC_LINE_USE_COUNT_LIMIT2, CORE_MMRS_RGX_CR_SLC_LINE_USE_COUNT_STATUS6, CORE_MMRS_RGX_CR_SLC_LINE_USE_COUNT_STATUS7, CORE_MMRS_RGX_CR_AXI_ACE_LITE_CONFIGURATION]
0x38A8 CORE_MMRS_RGX_CR_SLC_LINE_USE_COUNT_LIMIT2 — Define the maximum number of cache lines allowed to be allocated to each requester within the SLC. Note that values are specified per bank as a multiple of 4 cache lines with values of 0x0 denoting no limit. Also note that the specified values operate as soft limits rather than hard limits and at any given time a requestor may temporarily exceed its given cacheline limit by a small amount.
  [39:32] PM rw — Maximum number of cachelines allocated to the PM requestor
  [31:24] CDM rw — Maximum number of cachelines allocated to the CDM requestor
  [23:16] VDM rw — Maximum number of cachelines allocated to the VDM requestor
  [15:8] ISP rw — Maximum number of cachelines allocated to the ISP requestor
  [7:0] PBE rw — Maximum number of cachelines allocated to the PBE requestor
0x38B0 CORE_MMRS_RGX_CR_SLC_LINE_USE_COUNT_STATUS6 ro — Number of cache lines currently allocated to each requester within the SLC. Values will constantly change when the core is active but will give a representative snapshot of cache usage.
  [59:48] BANK0_CDM — Number of cache lines in bank 1 currently allocated to the CDM core
  [47:36] BANK1_ISP — Number of cache lines in bank 1 currently allocated to the ISP core
  [35:24] BANK0_ISP — Number of cache lines in bank 0 currently allocated to the ISP core
  [23:12] BANK1_PBE — Number of cache lines in bank 1 currently allocated to the PBE core
  [11:0] BANK0_PBE — Number of cache lines in bank 0 currently allocated to the PBE core
0x38B8 CORE_MMRS_RGX_CR_SLC_LINE_USE_COUNT_STATUS7 ro — Number of cache lines currently allocated to each requester within the SLC. Values will constantly change when the core is active but will give a representative snapshot of cache usage.
  [35:24] BANK1_VDM — Number of cache lines in bank 1 currently allocated to the VDM core
  [23:12] BANK0_VDM — Number of cache lines in bank 0 currently allocated to the VDM core
  [11:0] BANK1_CDM — Number of cache lines in bank 1 currently allocated to the CDM core
0x38C0 CORE_MMRS_RGX_CR_AXI_ACE_LITE_CONFIGURATION reset 0x88805000 — AXI ACE-LITE configuration registers
  [45] ENABLE_FENCE_OUT rw — SET to 1 to enable fence output to AXI
  [44:37] OSID_SECURITY rw — SET to 1 to disable secure reads/writes for each OSID
  [36] DISABLE_COHERENT_WRITELINEUNIQUE rw — SET to 1 to disable coherent write line uniques
  [35] DISABLE_COHERENT_WRITE rw — SET to 1 to disable coherent writes
  [34] DISABLE_COHERENT_READ rw — SET to 1 to disable coherent reads
  [33:30] ARCACHE_CACHE_MAINTENANCE rw — Read cache policy for cache maintenance transactions - bit[1] should be set to 1
  [29:26] ARCACHE_COHERENT rw — Read cache policy for coherent transactions - bit[1] should be set to 1
  [25:22] AWCACHE_COHERENT rw — Write cache policy for coherent transactions - bit[1] should be set to 1
  [21:20] ARDOMAIN_BARRIER rw — Read shareability domain for barrier transactions 00 = Non-Shareable 01 = Inner Shareable 10 = Outer Shareable 11 = System
  [19:18] AWDOMAIN_BARRIER rw — Write shareability domain for barrier transactions 00 = Non-Shareable 01 = Inner Shareable 10 = Outer Shareable 11 = System
  [17:16] ARDOMAIN_CACHE_MAINTENANCE rw — Read shareability domain for cache maintenance transactions 00 = Non-Shareable 01 = Inner Shareable 10 = Outer Shareable
  [15:14] AWDOMAIN_COHERENT rw — Write shareability domain for coherant transactions 01 = Inner Shareable 10 = Outer Shareable
  [13:12] ARDOMAIN_COHERENT rw — Read shareability domain for coherant transactions 01 = Inner Shareable 10 = Outer Shareable
  [11:10] ARDOMAIN_NON_SNOOPING rw — Read shareability domain for non-snooping transactions 00 = Non-Shareable 11 = System
  [9:8] AWDOMAIN_NON_SNOOPING rw — Write shareability domain for non-snooping transactions 00 = Non-Shareable 11 = System
  [7:4] ARCACHE_NON_SNOOPING rw — Read cache policy for non-snooping transactions
  [3:0] AWCACHE_NON_SNOOPING rw — Write cache policy for non-snooping transactions
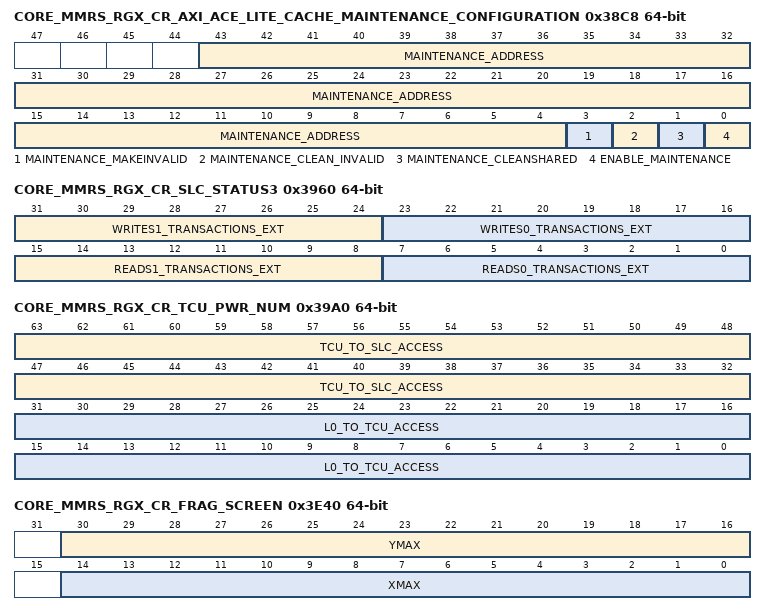
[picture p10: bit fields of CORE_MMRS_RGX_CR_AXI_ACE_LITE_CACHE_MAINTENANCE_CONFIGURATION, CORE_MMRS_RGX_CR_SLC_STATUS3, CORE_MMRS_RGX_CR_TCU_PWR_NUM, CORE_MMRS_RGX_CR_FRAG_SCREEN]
0x38C8 CORE_MMRS_RGX_CR_AXI_ACE_LITE_CACHE_MAINTENANCE_CONFIGURATION — AXI ACE-LITE Cache Maintenance configuration registers
  [43:4] MAINTENANCE_ADDRESS rw — Address to perform cache maintenace address on
  [3] MAINTENANCE_MAKEINVALID rw — Writing a 1 issues a makeinvalid operation
  [2] MAINTENANCE_CLEAN_INVALID rw — Writing a 1 issues a clean invalid operation
  [1] MAINTENANCE_CLEANSHARED rw — Writing a 1 issues a clean shared operation
  [0] ENABLE_MAINTENANCE rw — Writing a 1 enables cache maintenance operations
0x38D0 CORE_MMRS_RGX_CR_AXI_ACE_LITE_CACHE_MAINTENANCE_STATUS — The hardware will set this to 1 once the cache maintenance operation has completed. The firmware should poll this bit and set it to 0, once it has acknowledged it being set to 1.
  [0] DONE rw
0x3930 CORE_MMRS_RGX_CR_SLC_CTRL_MISC2 — SLC control registers
  [31:0] SCRAMBLE_BITS rw — Pattern of bits used to determine the MSB of the Cache Bank in 4 Bank configurations in Address Decode mode 0x21. The actual Cache Bank to use is determined by indexing into the 32 Scramble Bits using the 5 LSB's of the Hash result and then XORing this with Bit 6 of the incoming address to give a single bit result
0x3938 CORE_MMRS_RGX_CR_SLC_CROSSBAR_LOAD_BALANCE — SLC control registers to bypass SLC crossbar load balancing
  [0] BYPASS rw — control register bit to bypass load balancing in SLC crossbar. In this case, the requests from img-memif0 will go directly to ocp-memif0 and so on
0x3960 CORE_MMRS_RGX_CR_SLC_STATUS3 ro — Current status of the SLC
  [31:24] WRITES1_TRANSACTIONS_EXT — Number of outsanding write burst transactions in SLC bank 1
  [23:16] WRITES0_TRANSACTIONS_EXT — Number of outsanding write burst transactions in SLC bank 0
  [15:8] READS1_TRANSACTIONS_EXT — Number of outsanding read burst transactions in SLC bank 1
  [7:0] READS0_TRANSACTIONS_EXT — Number of outsanding read burst transactions in SLC bank 0
0x3970 CORE_MMRS_RGX_CR_SLC_SIZE_IN_KB ro reset 0x100 — Configured SLC SIZE in KBytes
  [15:0] SIZE — The configured SLC SIZE in KBytes ie 0x0100 = 256 KB.
0x39A0 CORE_MMRS_RGX_CR_TCU_PWR_NUM ro — Power Monitoring register
  [63:32] TCU_TO_SLC_ACCESS — Number of TCU to SLC accesses
  [31:0] L0_TO_TCU_ACCESS — Number of MADD-L0 to TCU accesses
0x39B0 CORE_MMRS_RGX_CR_TCU_CTRL — TCU control regiseters
  [0] SLC_CP_LAZYWB_OVERRIDE rw — Override the TCU to SLC cache policy from lazy write back to write back
0x3E40 CORE_MMRS_RGX_CR_FRAG_SCREEN — Define the screen size for fragment processing. Pixels on the screen are numbered (0,0) top left, to (XMAX, YMAX) bottom right.
  [30:16] YMAX rw — Maximum pixel number in y dimension on screen. Screen height in pixels is YMAX+1. 16K x 16K is the max screen size. I.e. 2^14, bit 15 is always written as 0.
  [14:0] XMAX rw — Maximum pixel number in x dimension on screen. Screen width in pixels is XMAX+1. 16K x 16K is the max screen size. I.e. 2^14, bit 15 is always written as 0.
0x4000 CORE_MMRS_RGX_CR_USC_INST_CACHE
  [0] INVALIDATE wo — Any write to this location invalidates the L1 and L2 instruction caches automatically
0x4008 CORE_MMRS_RGX_CR_USC_CODE_BASE_VERTEX
  [39:6] ADDR rw — Vertex Data Master Code Base Register bits
0x4010 CORE_MMRS_RGX_CR_USC_CODE_BASE_PIXEL
  [39:6] ADDR rw — Pixel Data Master Code Base Register bits
0x4028 CORE_MMRS_RGX_CR_USC_CODE_BASE_COMPUTE
  [39:6] ADDR rw — Compute Data Master Code Base Register bits
0x4030 CORE_MMRS_RGX_CR_USC_BREAKPOINT
  [31:1] ADDR rw — Breakpoint Address
0x4038 CORE_MMRS_RGX_CR_USC_BREAKPOINT_HANDLER
  [31:1] ADDR rw — Breakpoint Handler Address
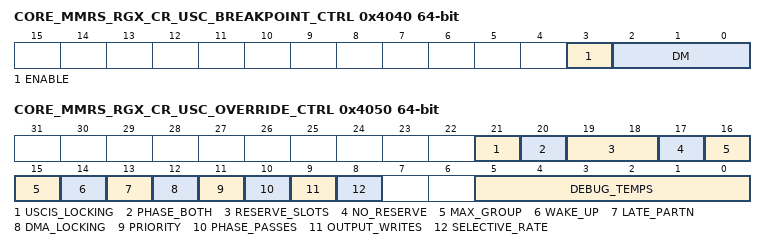
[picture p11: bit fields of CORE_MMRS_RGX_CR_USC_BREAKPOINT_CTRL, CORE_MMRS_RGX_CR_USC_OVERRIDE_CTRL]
0x4040 CORE_MMRS_RGX_CR_USC_BREAKPOINT_CTRL
  [3] ENABLE rw — 0 = Breakpoint disabled, 1 = Breakpoint enabled
  [2:0] DM rw — Data Master of Breakpoint
0x4048 CORE_MMRS_RGX_CR_USC_SMP_SWAP
  [0] ENABLE rw — Deactivate after SMP instruction
0x4050 CORE_MMRS_RGX_CR_USC_OVERRIDE_CTRL
  [21] USCIS_LOCKING rw — 0 = Default, enable locking of USCIS when queue fills to maintain task ordering, 1 = retry USCIS request
  [20] PHASE_BOTH rw — 0 = Default, no extra pass groups when single phase followed by multi-phase, 1 = generate pass group whenever phases per task changes
  [19:18] RESERVE_SLOTS rw — 0 = Default, allow all slots to be used for first phase tasks, 1 = reserve 1 slot, 2 = reserve 2, 3 = reserve 4
  [17] NO_RESERVE rw — 0 = Default, reserve slots for second phases, 1 = Do not reserve slots for second phase tasks
  [16:15] MAX_GROUP rw — 0 = Default - 8 pass groups in flight, 1 = 6 pass groups, 2 = 4 pass groups, 3 = 2 pass groups. To disable entirely see PDS
  [14] WAKE_UP rw — 0 = Default, normal wake up, 1 = force task wake up
  [13] LATE_PARTN rw — 0 = Default, enable pixel data master tasks to start before a partition is allocated, 1 = wait for partition
  [12] DMA_LOCKING rw — 0 = Default, enable locking of DMA when queue fills to maintain task ordering, 1 = retry DMA request
  [11] PRIORITY rw — 0 = Default, enable state loading and end of tile tasks to run with higher priority, 1 = all tasks low priority
  [10] PHASE_PASSES rw — 0 = Default, enable inferred pass groups when multiple phase tasks are encountered, 1 = disable, hard SDs must be used
  [9] OUTPUT_WRITES rw — 0 = Default, enable tracking of output buffer write completion for on-edge buffer validlity, 1 = tracking invalid
  [8] SELECTIVE_RATE rw — 0 = Default, [core specific, enable selective rate mode if functional], 1 = disable
  [5:0] DEBUG_TEMPS rw — Number of temps to add to PDS allocation size for debugging. Units of 8
